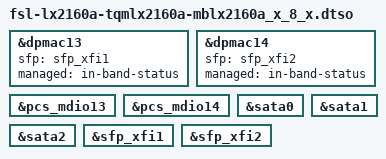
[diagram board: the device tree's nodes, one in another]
// SPDX-License-Identifier: GPL-2.0-or-later OR MIT
/*
 * Copyright (c) 2020-2023 TQ-Systems GmbH <linux@ew.tq-group.com>,
 * D-82229 Seefeld, Germany.
 * Author: Gregor Herburger
 */

/dts-v1/;
/plugin/;

&dpmac13 {
	sfp = <&sfp_xfi1>;
	managed = "in-band-status";
};

&dpmac14 {
	sfp = <&sfp_xfi2>;
	managed = "in-band-status";
};

&pcs_mdio13 {
	status = "okay";
};

&pcs_mdio14 {
	status = "okay";
};

&sata0 {
	status = "okay";
};

&sata1 {
	status = "okay";
};

&sata2 {
	status = "okay";
};

&sfp_xfi1 {
	status = "okay";
};

&sfp_xfi2 {
	status = "okay";
};
